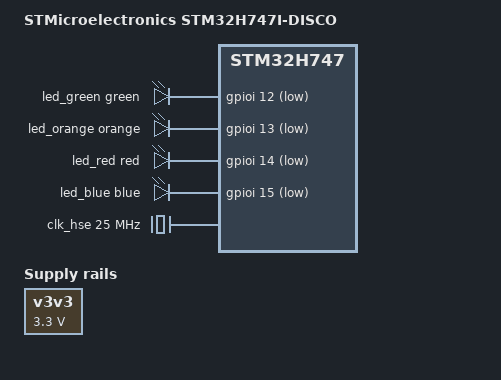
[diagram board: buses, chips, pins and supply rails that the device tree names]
// SPDX-FileCopyrightText: 2026 Core Devices LLC
// SPDX-License-Identifier: (GPL-2.0-only OR BSD-2-Clause)

// The kit, as both cores see it: each core's tree enables what it uses

#include "stm32h747i_disco-pinctrl.dtsi"

#include <dt-bindings/gpio/gpio.h>
#include <dt-bindings/input/input.h>
#include <dt-bindings/leds/common.h>

/ {
	model = "STMicroelectronics STM32H747I-DISCO";
	compatible = "st,stm32h747i-disco", "st,stm32h747";

	v3v3: regulator-3v3 {
		compatible = "regulator-fixed";
		regulator-name = "v3v3";
		regulator-min-microvolt = <3300000>;
		regulator-max-microvolt = <3300000>;
		regulator-always-on;
	};

	leds {
		compatible = "gpio-leds";

		led_green: led-green {
			color = <LED_COLOR_ID_GREEN>;
			gpios = <&gpioi 12 GPIO_ACTIVE_LOW>;
		};

		led_orange: led-orange {
			color = <LED_COLOR_ID_ORANGE>;
			gpios = <&gpioi 13 GPIO_ACTIVE_LOW>;
		};

		led_red: led-red {
			color = <LED_COLOR_ID_RED>;
			gpios = <&gpioi 14 GPIO_ACTIVE_LOW>;
		};

		led_blue: led-blue {
			color = <LED_COLOR_ID_BLUE>;
			gpios = <&gpioi 15 GPIO_ACTIVE_LOW>;
		};
	};
};

&clk_hse {
	clock-frequency = <25000000>;
};

// The SMPS supplies VCORE, as the kit ships
&pwr {
	st,supply-config = "direct-smps";
};
